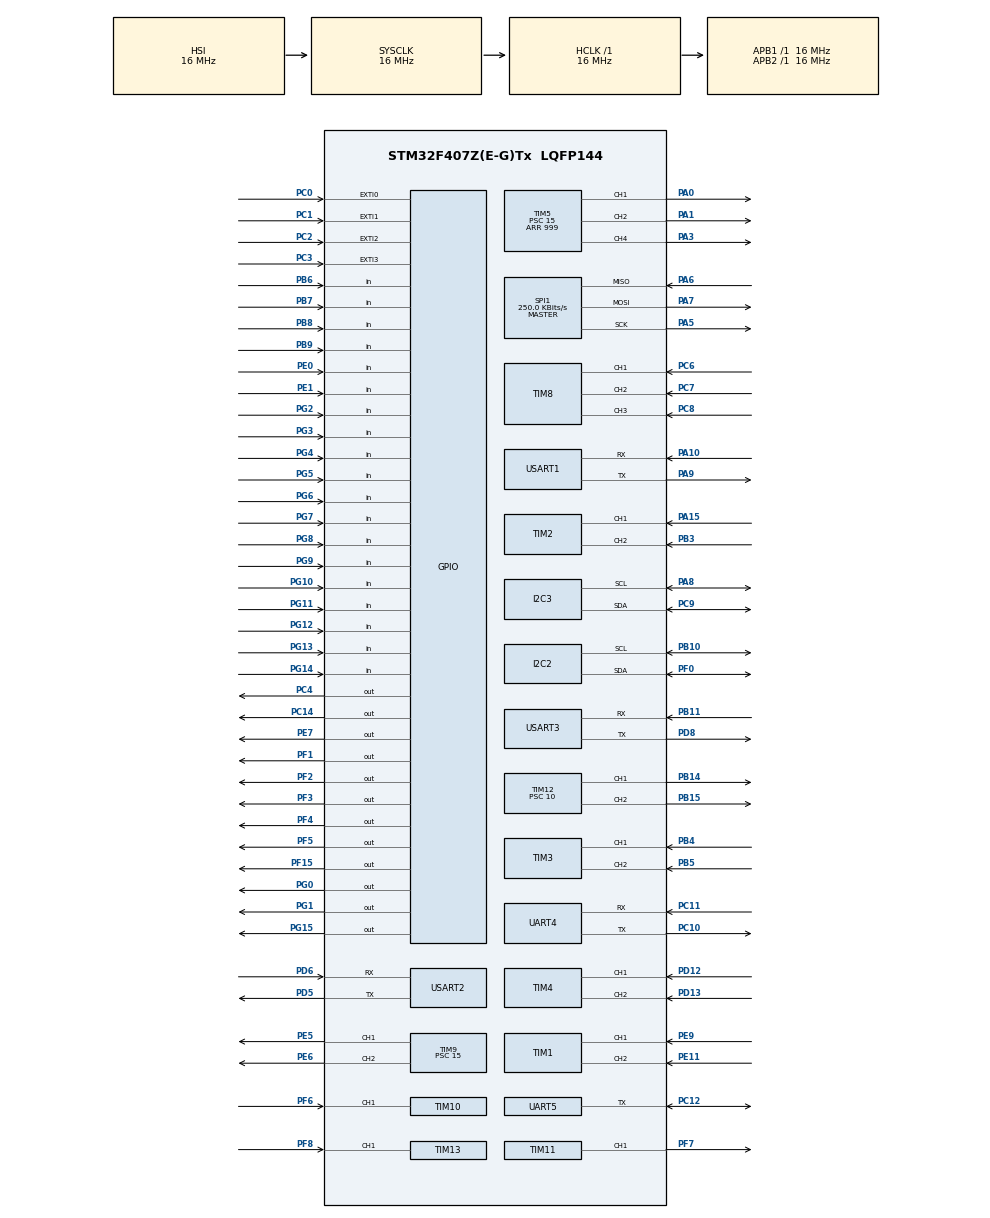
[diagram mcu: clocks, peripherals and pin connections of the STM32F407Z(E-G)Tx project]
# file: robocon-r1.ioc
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Dma.Request0=USART2_RX
Dma.USART2_RX.0.Direction=DMA_PERIPH_TO_MEMORY
Dma.USART2_RX.0.FIFOMode=DMA_FIFOMODE_DISABLE
Dma.USART2_RX.0.Instance=DMA1_Stream5
Dma.USART2_RX.0.MemDataAlignment=DMA_MDATAALIGN_BYTE
Dma.USART2_RX.0.MemInc=DMA_MINC_ENABLE
Dma.USART2_RX.0.Mode=DMA_NORMAL
Dma.USART2_RX.0.PeriphDataAlignment=DMA_PDATAALIGN_BYTE
Dma.USART2_RX.0.PeriphInc=DMA_PINC_DISABLE
Dma.USART2_RX.0.Priority=DMA_PRIORITY_LOW
FREERTOS.Tasks01=defaultTask,24,128,StartDefaultTask,Default,NULL,Dynamic,NULL,NULL
Mcu.Family=STM32F4
Mcu.Name=STM32F407Z(E-G)Tx
Mcu.Package=LQFP144
NVIC.DMA1_Stream5_IRQn=true\:5\:0\:false\:false\:true\:true\:false\:true\:true
NVIC.I2C3_EV_IRQn=true\:5\:0\:false\:false\:true\:true\:true\:true\:true
NVIC.PriorityGroup=NVIC_PRIORITYGROUP_4
NVIC.TIM7_IRQn=true\:15\:0\:false\:false\:true\:false\:false\:true\:true
NVIC.TimeBase=TIM7_IRQn
NVIC.TimeBaseIP=TIM7
NVIC.UART4_IRQn=true\:5\:0\:false\:false\:true\:true\:true\:true\:true
NVIC.UART5_IRQn=true\:5\:0\:false\:false\:true\:true\:true\:true\:true
NVIC.USART1_IRQn=true\:5\:0\:false\:false\:true\:true\:true\:true\:true
NVIC.USART2_IRQn=true\:5\:0\:false\:false\:true\:true\:true\:true\:true
NVIC.USART3_IRQn=true\:5\:0\:false\:false\:true\:true\:true\:true\:true
PA0-WKUP.Signal=S_TIM5_CH1
PA1.Signal=S_TIM5_CH2
PA10.Mode=Asynchronous
PA10.Signal=USART1_RX
PA13.Mode=Serial_Wire
PA13.Signal=SYS_JTMS-SWDIO
PA14.Mode=Serial_Wire
PA14.Signal=SYS_JTCK-SWCLK
PA15.Signal=S_TIM2_CH1_ETR
PA3.Signal=S_TIM5_CH4
PA5.Mode=Full_Duplex_Master
PA5.Signal=SPI1_SCK
PA6.Mode=Full_Duplex_Master
PA6.Signal=SPI1_MISO
PA7.Mode=Full_Duplex_Master
PA7.Signal=SPI1_MOSI
PA8.Mode=I2C
PA8.Signal=I2C3_SCL
PA9.Mode=Asynchronous
PA9.Signal=USART1_TX
PB10.Mode=I2C
PB10.Signal=I2C2_SCL
PB11.Mode=Asynchronous
PB11.Signal=USART3_RX
PB14.Signal=S_TIM12_CH1
PB15.Signal=S_TIM12_CH2
PB3.Signal=S_TIM2_CH2
PB4.Signal=S_TIM3_CH1
PB5.Signal=S_TIM3_CH2
PB6.Signal=GPIO_Input
PB7.Signal=GPIO_Input
PB8.Signal=GPIO_Input
PB9.Signal=GPIO_Input
PC0.Signal=GPXTI0
PC1.Signal=GPXTI1
PC10.Mode=Asynchronous
PC10.Signal=UART4_TX
PC11.Mode=Asynchronous
PC11.Signal=UART4_RX
PC12.Mode=Half_duplex(single_wire_mode)
PC12.Signal=UART5_TX
PC14-OSC32_IN.Signal=GPIO_Output
PC2.Signal=GPXTI2
PC3.Signal=GPXTI3
PC4.Signal=GPIO_Output
PC6.Signal=S_TIM8_CH1
PC7.Signal=S_TIM8_CH2
PC8.Signal=S_TIM8_CH3
PC9.Mode=I2C
PC9.Signal=I2C3_SDA
PD12.Signal=S_TIM4_CH1
PD13.Signal=S_TIM4_CH2
PD5.Mode=Asynchronous
PD5.Signal=USART2_TX
PD6.GPIO_PuPd=GPIO_NOPULL
PD6.Mode=Asynchronous
PD6.Signal=USART2_RX
PD8.Mode=Asynchronous
PD8.Signal=USART3_TX
PE0.Signal=GPIO_Input
PE1.Signal=GPIO_Input
PE11.Signal=S_TIM1_CH2
PE5.Signal=S_TIM9_CH1
PE6.Signal=S_TIM9_CH2
PE7.Signal=GPIO_Output
PE9.Signal=S_TIM1_CH1
PF0.Mode=I2C
PF0.Signal=I2C2_SDA
PF1.Signal=GPIO_Output
PF15.Signal=GPIO_Output
PF2.Signal=GPIO_Output
PF3.Signal=GPIO_Output
PF4.Signal=GPIO_Output
PF5.Signal=GPIO_Output
PF6.Signal=S_TIM10_CH1
PF7.Signal=S_TIM11_CH1
PF8.Signal=S_TIM13_CH1
PG0.Signal=GPIO_Output
PG1.Signal=GPIO_Output
PG10.Signal=GPIO_Input
PG11.Signal=GPIO_Input
PG12.Signal=GPIO_Input
PG13.Signal=GPIO_Input
PG14.Signal=GPIO_Input
PG15.Signal=GPIO_Output
PG2.Signal=GPIO_Input
PG3.Signal=GPIO_Input
PG4.Signal=GPIO_Input
PG5.Signal=GPIO_Input
PG6.Signal=GPIO_Input
PG7.Signal=GPIO_Input
PG8.Signal=GPIO_Input
PG9.Signal=GPIO_Input
ProjectManager.HeapSize=0x200
ProjectManager.StackSize=0x400
ProjectManager.TargetToolchain=CMake
RCC.AHBFreq_Value=16000000
RCC.APB1Freq_Value=16000000
RCC.APB2Freq_Value=16000000
RCC.CortexFreq_Value=16000000
RCC.HSE_VALUE=25000000
RCC.HSI_VALUE=16000000
RCC.LSE_VALUE=32768
RCC.SYSCLKFreq_VALUE=16000000
RCC.VCOOutputFreq_Value=192000000
SH.S_TIM10_CH1.0=TIM10_CH1,Input_Capture1_from_TI1
SH.S_TIM11_CH1.0=TIM11_CH1,PWM Generation1 CH1
SH.S_TIM12_CH1.0=TIM12_CH1,PWM Generation1 CH1
SH.S_TIM12_CH2.0=TIM12_CH2,PWM Generation2 CH2
SH.S_TIM13_CH1.0=TIM13_CH1,Input_Capture1_from_TI1
SH.S_TIM1_CH1.0=TIM1_CH1,Encoder_Interface
SH.S_TIM1_CH2.0=TIM1_CH2,Encoder_Interface
SH.S_TIM2_CH1_ETR.0=TIM2_CH1,Encoder_Interface
SH.S_TIM2_CH2.0=TIM2_CH2,Encoder_Interface
SH.S_TIM3_CH1.0=TIM3_CH1,Encoder_Interface
SH.S_TIM3_CH2.0=TIM3_CH2,Encoder_Interface
SH.S_TIM4_CH1.0=TIM4_CH1,Encoder_Interface
SH.S_TIM4_CH2.0=TIM4_CH2,Encoder_Interface
SH.S_TIM5_CH1.0=TIM5_CH1,PWM Generation1 CH1
SH.S_TIM5_CH2.0=TIM5_CH2,PWM Generation2 CH2
SH.S_TIM5_CH4.0=TIM5_CH4,PWM Generation4 CH4
SH.S_TIM8_CH1.0=TIM8_CH1,Input_Capture1_from_TI1
SH.S_TIM8_CH2.0=TIM8_CH2,Input_Capture2_from_TI2
SH.S_TIM8_CH3.0=TIM8_CH3,Input_Capture3_from_TI3
SH.S_TIM9_CH1.0=TIM9_CH1,PWM Generation1 CH1
SH.S_TIM9_CH2.0=TIM9_CH2,PWM Generation2 CH2
SPI1.BaudRatePrescaler=SPI_BAUDRATEPRESCALER_64
SPI1.CLKPhase=SPI_PHASE_2EDGE
SPI1.CLKPolarity=SPI_POLARITY_HIGH
SPI1.CalculateBaudRate=250.0 KBits/s
SPI1.Direction=SPI_DIRECTION_2LINES
SPI1.FirstBit=SPI_FIRSTBIT_LSB
SPI1.Mode=SPI_MODE_MASTER
SPI1.VirtualType=VM_MASTER
TIM10.Channel=TIM_CHANNEL_1
TIM11.Channel=TIM_CHANNEL_1
TIM12.Channel-PWM\ Generation1\ CH1=TIM_CHANNEL_1
TIM12.Channel-PWM\ Generation2\ CH2=TIM_CHANNEL_2
TIM12.Period=999
TIM12.Prescaler=10
TIM13.Channel=TIM_CHANNEL_1
TIM5.Channel-PWM\ Generation1\ CH1=TIM_CHANNEL_1
TIM5.Channel-PWM\ Generation2\ CH2=TIM_CHANNEL_2
TIM5.Channel-PWM\ Generation4\ CH4=TIM_CHANNEL_4
TIM5.Period=999
TIM5.Prescaler=15
TIM5.Pulse-PWM\ Generation1\ CH1=0
TIM5.Pulse-PWM\ Generation2\ CH2=0
TIM8.Channel-Input_Capture1_from_TI1=TIM_CHANNEL_1
TIM8.Channel-Input_Capture2_from_TI2=TIM_CHANNEL_2
TIM8.Channel-Input_Capture3_from_TI3=TIM_CHANNEL_3
TIM9.Channel-PWM\ Generation1\ CH1=TIM_CHANNEL_1
TIM9.Channel-PWM\ Generation2\ CH2=TIM_CHANNEL_2
TIM9.Period=999
TIM9.Prescaler=15
UART4.VirtualMode=Asynchronous
UART5.VirtualMode=Asynchronous
USART1.VirtualMode=VM_ASYNC
USART2.VirtualMode=VM_ASYNC
USART3.VirtualMode=VM_ASYNC
VP_FREERTOS_VS_CMSIS_V2.Mode=CMSIS_V2
VP_SYS_VS_tim7.Mode=TIM7
VP_TIM10_VS_ClockSourceINT.Mode=Enable_Timer
VP_TIM11_VS_ClockSourceINT.Mode=Enable_Timer
VP_TIM13_VS_ClockSourceINT.Mode=Enable_Timer
VP_TIM8_VS_ClockSourceINT.Mode=Internal
board=custom

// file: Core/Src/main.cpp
/* USER CODE BEGIN Header */
/**
  ******************************************************************************
  * @file           : main.c
  * @brief          : Main program body
  ******************************************************************************
  * @attention
  *
  * Copyright (c) 2026 STMicroelectronics.
  * All rights reserved.
  *
  * This software is licensed under terms that can be found in the LICENSE file
  * in the root directory of this software component.
  * If no LICENSE file comes with this software, it is provided AS-IS.
  *
  ******************************************************************************
  */
/* USER CODE END Header */
#include "main.h"
#include "cmsis_os.h"

/* USER CODE BEGIN Includes */
#include "entry_point.hpp"
#include "bsp_atk_ms901m.hpp"
#include "stm32f4xx_hal_uart.h"
#include "user_controller.hpp"
/* USER CODE END Includes */

I2C_HandleTypeDef hi2c2;
I2C_HandleTypeDef hi2c3;

SPI_HandleTypeDef hspi1;

TIM_HandleTypeDef htim1;
TIM_HandleTypeDef htim2;
TIM_HandleTypeDef htim3;
TIM_HandleTypeDef htim4;
TIM_HandleTypeDef htim5;
TIM_HandleTypeDef htim8;
TIM_HandleTypeDef htim9;
TIM_HandleTypeDef htim10;
TIM_HandleTypeDef htim11;
TIM_HandleTypeDef htim12;
TIM_HandleTypeDef htim13;

UART_HandleTypeDef huart4;
UART_HandleTypeDef huart5;
UART_HandleTypeDef huart1;
UART_HandleTypeDef huart2;
UART_HandleTypeDef huart3;
DMA_HandleTypeDef hdma_usart2_rx;

/* Definitions for defaultTask */
osThreadId_t defaultTaskHandle;
const osThreadAttr_t defaultTask_attributes = {
  .name = "defaultTask",
  .stack_size = 4096,
  .priority = (osPriority_t) osPriorityNormal,
};

void SystemClock_Config(void);
static void MX_GPIO_Init(void);
static void MX_DMA_Init(void);
static void MX_SPI1_Init(void);
static void MX_TIM1_Init(void);
static void MX_TIM2_Init(void);
static void MX_TIM3_Init(void);
static void MX_TIM4_Init(void);
static void MX_UART4_Init(void);
static void MX_TIM8_Init(void);
static void MX_TIM9_Init(void);
static void MX_TIM10_Init(void);
static void MX_TIM11_Init(void);
static void MX_TIM12_Init(void);
static void MX_TIM13_Init(void);
static void MX_I2C2_Init(void);
static void MX_I2C3_Init(void);
static void MX_UART5_Init(void);
static void MX_USART1_UART_Init(void);
static void MX_USART2_UART_Init(void);
static void MX_USART3_UART_Init(void);
static void MX_TIM5_Init(void);
void StartDefaultTask(void *argument);

/* USER CODE BEGIN 0 */
gdut::i2c i2c3{&hi2c3};
gdut::pca9685 pca9685_ctrl{i2c3, gdut::pca9685::default_address};
/* USER CODE END 0 */

int main(void)
{

  /* MCU Configuration--------------------------------------------------------*/

  /* Reset of all peripherals, Initializes the Flash interface and the Systick. */
  HAL_Init();

  /* Configure the system clock */
  SystemClock_Config();

  /* Initialize all configured peripherals */
  MX_GPIO_Init();
  MX_DMA_Init();
  MX_SPI1_Init();
  MX_TIM1_Init();
  MX_TIM2_Init();
  MX_TIM3_Init();
  MX_TIM4_Init();
  MX_UART4_Init();
  MX_TIM8_Init();
  MX_TIM9_Init();
  MX_TIM10_Init();
  MX_TIM11_Init();
  MX_TIM12_Init();
  MX_TIM13_Init();
  MX_I2C2_Init();
  MX_I2C3_Init();
  MX_UART5_Init();
  MX_USART1_UART_Init();
  MX_USART2_UART_Init();
  MX_USART3_UART_Init();
  MX_TIM5_Init();

  /* Init scheduler */
  osKernelInitialize();

  /* USER CODE BEGIN RTOS_QUEUES */
  /* add queues, ... */
  gdut::entry_point::instance().init(
   &pca9685_ctrl, &hi2c2,&hi2c3, &hspi1, &htim1,
   &htim2, &htim3, &htim4, &htim5,
   &htim8, &htim9, &htim10, &htim11, &htim12, &htim13,
   &huart4, &huart5, &huart1, &huart2, &huart3);
  /* USER CODE END RTOS_QUEUES */

  /* Create the thread(s) */
  /* creation of defaultTask */
  defaultTaskHandle = osThreadNew(StartDefaultTask, NULL, &defaultTask_attributes);

  /* Start scheduler */
  osKernelStart();

  /* We should never get here as control is now taken by the scheduler */

  /* Infinite loop */
  while (1)
  {

  }
}

void SystemClock_Config(void)
{
  RCC_OscInitTypeDef RCC_OscInitStruct = {0};
  RCC_ClkInitTypeDef RCC_ClkInitStruct = {0};

  /** Configure the main internal regulator output voltage
  */
  __HAL_RCC_PWR_CLK_ENABLE();
  __HAL_PWR_VOLTAGESCALING_CONFIG(PWR_REGULATOR_VOLTAGE_SCALE1);

  /** Initializes the RCC Oscillators according to the specified parameters
  * in the RCC_OscInitTypeDef structure.
  */
  RCC_OscInitStruct.OscillatorType = RCC_OSCILLATORTYPE_HSI;
  RCC_OscInitStruct.HSIState = RCC_HSI_ON;
  RCC_OscInitStruct.HSICalibrationValue = RCC_HSICALIBRATION_DEFAULT;
  RCC_OscInitStruct.PLL.PLLState = RCC_PLL_NONE;
  if (HAL_RCC_OscConfig(&RCC_OscInitStruct) != HAL_OK)
  {
    Error_Handler();
  }

  /** Initializes the CPU, AHB and APB buses clocks
  */
  RCC_ClkInitStruct.ClockType = RCC_CLOCKTYPE_HCLK|RCC_CLOCKTYPE_SYSCLK
                              |RCC_CLOCKTYPE_PCLK1|RCC_CLOCKTYPE_PCLK2;
  RCC_ClkInitStruct.SYSCLKSource = RCC_SYSCLKSOURCE_HSI;
  RCC_ClkInitStruct.AHBCLKDivider = RCC_SYSCLK_DIV1;
  RCC_ClkInitStruct.APB1CLKDivider = RCC_HCLK_DIV1;
  RCC_ClkInitStruct.APB2CLKDivider = RCC_HCLK_DIV1;

  if (HAL_RCC_ClockConfig(&RCC_ClkInitStruct, FLASH_LATENCY_0) != HAL_OK)
  {
    Error_Handler();
  }
}

static void MX_I2C2_Init(void)
{

  hi2c2.Instance = I2C2;
  hi2c2.Init.ClockSpeed = 100000;
  hi2c2.Init.DutyCycle = I2C_DUTYCYCLE_2;
  hi2c2.Init.OwnAddress1 = 0;
  hi2c2.Init.AddressingMode = I2C_ADDRESSINGMODE_7BIT;
  hi2c2.Init.DualAddressMode = I2C_DUALADDRESS_DISABLE;
  hi2c2.Init.OwnAddress2 = 0;
  hi2c2.Init.GeneralCallMode = I2C_GENERALCALL_DISABLE;
  hi2c2.Init.NoStretchMode = I2C_NOSTRETCH_DISABLE;
  if (HAL_I2C_Init(&hi2c2) != HAL_OK)
  {
    Error_Handler();
  }

}

static void MX_I2C3_Init(void)
{

  hi2c3.Instance = I2C3;
  hi2c3.Init.ClockSpeed = 100000;
  hi2c3.Init.DutyCycle = I2C_DUTYCYCLE_2;
  hi2c3.Init.OwnAddress1 = 0;
  hi2c3.Init.AddressingMode = I2C_ADDRESSINGMODE_7BIT;
  hi2c3.Init.DualAddressMode = I2C_DUALADDRESS_DISABLE;
  hi2c3.Init.OwnAddress2 = 0;
  hi2c3.Init.GeneralCallMode = I2C_GENERALCALL_DISABLE;
  hi2c3.Init.NoStretchMode = I2C_NOSTRETCH_DISABLE;
  if (HAL_I2C_Init(&hi2c3) != HAL_OK)
  {
    Error_Handler();
  }

}

static void MX_SPI1_Init(void)
{

  /* SPI1 parameter configuration*/
  hspi1.Instance = SPI1;
  hspi1.Init.Mode = SPI_MODE_MASTER;
  hspi1.Init.Direction = SPI_DIRECTION_2LINES;
  hspi1.Init.DataSize = SPI_DATASIZE_8BIT;
  hspi1.Init.CLKPolarity = SPI_POLARITY_HIGH;
  hspi1.Init.CLKPhase = SPI_PHASE_2EDGE;
  hspi1.Init.NSS = SPI_NSS_SOFT;
  hspi1.Init.BaudRatePrescaler = SPI_BAUDRATEPRESCALER_64;
  hspi1.Init.FirstBit = SPI_FIRSTBIT_LSB;
  hspi1.Init.TIMode = SPI_TIMODE_DISABLE;
  hspi1.Init.CRCCalculation = SPI_CRCCALCULATION_DISABLE;
  hspi1.Init.CRCPolynomial = 10;
  if (HAL_SPI_Init(&hspi1) != HAL_OK)
  {
    Error_Handler();
  }

}

static void MX_TIM1_Init(void)
{

  TIM_Encoder_InitTypeDef sConfig = {0};
  TIM_MasterConfigTypeDef sMasterConfig = {0};

  htim1.Instance = TIM1;
  htim1.Init.Prescaler = 0;
  htim1.Init.CounterMode = TIM_COUNTERMODE_UP;
  htim1.Init.Period = 65535;
  htim1.Init.ClockDivision = TIM_CLOCKDIVISION_DIV1;
  htim1.Init.RepetitionCounter = 0;
  htim1.Init.AutoReloadPreload = TIM_AUTORELOAD_PRELOAD_DISABLE;
  sConfig.EncoderMode = TIM_ENCODERMODE_TI1;
  sConfig.IC1Polarity = TIM_ICPOLARITY_RISING;
  sConfig.IC1Selection = TIM_ICSELECTION_DIRECTTI;
  sConfig.IC1Prescaler = TIM_ICPSC_DIV1;
  sConfig.IC1Filter = 0;
  sConfig.IC2Polarity = TIM_ICPOLARITY_RISING;
  sConfig.IC2Selection = TIM_ICSELECTION_DIRECTTI;
  sConfig.IC2Prescaler = TIM_ICPSC_DIV1;
  sConfig.IC2Filter = 0;
  if (HAL_TIM_Encoder_Init(&htim1, &sConfig) != HAL_OK)
  {
    Error_Handler();
  }
  sMasterConfig.MasterOutputTrigger = TIM_TRGO_RESET;
  sMasterConfig.MasterSlaveMode = TIM_MASTERSLAVEMODE_DISABLE;
  if (HAL_TIMEx_MasterConfigSynchronization(&htim1, &sMasterConfig) != HAL_OK)
  {
    Error_Handler();
  }

}

static void MX_TIM2_Init(void)
{

  TIM_Encoder_InitTypeDef sConfig = {0};
  TIM_MasterConfigTypeDef sMasterConfig = {0};

  htim2.Instance = TIM2;
  htim2.Init.Prescaler = 0;
  htim2.Init.CounterMode = TIM_COUNTERMODE_UP;
  htim2.Init.Period = 4294967295;
  htim2.Init.ClockDivision = TIM_CLOCKDIVISION_DIV1;
  htim2.Init.AutoReloadPreload = TIM_AUTORELOAD_PRELOAD_DISABLE;
  sConfig.EncoderMode = TIM_ENCODERMODE_TI1;
  sConfig.IC1Polarity = TIM_ICPOLARITY_RISING;
  sConfig.IC1Selection = TIM_ICSELECTION_DIRECTTI;
  sConfig.IC1Prescaler = TIM_ICPSC_DIV1;
  sConfig.IC1Filter = 0;
  sConfig.IC2Polarity = TIM_ICPOLARITY_RISING;
  sConfig.IC2Selection = TIM_ICSELECTION_DIRECTTI;
  sConfig.IC2Prescaler = TIM_ICPSC_DIV1;
  sConfig.IC2Filter = 0;
  if (HAL_TIM_Encoder_Init(&htim2, &sConfig) != HAL_OK)
  {
    Error_Handler();
  }
  sMasterConfig.MasterOutputTrigger = TIM_TRGO_RESET;
  sMasterConfig.MasterSlaveMode = TIM_MASTERSLAVEMODE_DISABLE;
  if (HAL_TIMEx_MasterConfigSynchronization(&htim2, &sMasterConfig) != HAL_OK)
  {
    Error_Handler();
  }

}

static void MX_TIM3_Init(void)
{

  TIM_Encoder_InitTypeDef sConfig = {0};
  TIM_MasterConfigTypeDef sMasterConfig = {0};

  htim3.Instance = TIM3;
  htim3.Init.Prescaler = 0;
  htim3.Init.CounterMode = TIM_COUNTERMODE_UP;
  htim3.Init.Period = 65535;
  htim3.Init.ClockDivision = TIM_CLOCKDIVISION_DIV1;
  htim3.Init.AutoReloadPreload = TIM_AUTORELOAD_PRELOAD_DISABLE;
  sConfig.EncoderMode = TIM_ENCODERMODE_TI1;
  sConfig.IC1Polarity = TIM_ICPOLARITY_RISING;
  sConfig.IC1Selection = TIM_ICSELECTION_DIRECTTI;
  sConfig.IC1Prescaler = TIM_ICPSC_DIV1;
  sConfig.IC1Filter = 0;
  sConfig.IC2Polarity = TIM_ICPOLARITY_RISING;
  sConfig.IC2Selection = TIM_ICSELECTION_DIRECTTI;
  sConfig.IC2Prescaler = TIM_ICPSC_DIV1;
  sConfig.IC2Filter = 0;
  if (HAL_TIM_Encoder_Init(&htim3, &sConfig) != HAL_OK)
  {
    Error_Handler();
  }
  sMasterConfig.MasterOutputTrigger = TIM_TRGO_RESET;
  sMasterConfig.MasterSlaveMode = TIM_MASTERSLAVEMODE_DISABLE;
  if (HAL_TIMEx_MasterConfigSynchronization(&htim3, &sMasterConfig) != HAL_OK)
  {
    Error_Handler();
  }

}

static void MX_TIM4_Init(void)
{

  TIM_Encoder_InitTypeDef sConfig = {0};
  TIM_MasterConfigTypeDef sMasterConfig = {0};

  htim4.Instance = TIM4;
  htim4.Init.Prescaler = 0;
  htim4.Init.CounterMode = TIM_COUNTERMODE_UP;
  htim4.Init.Period = 65535;
  htim4.Init.ClockDivision = TIM_CLOCKDIVISION_DIV1;
  htim4.Init.AutoReloadPreload = TIM_AUTORELOAD_PRELOAD_DISABLE;
  sConfig.EncoderMode = TIM_ENCODERMODE_TI1;
  sConfig.IC1Polarity = TIM_ICPOLARITY_RISING;
  sConfig.IC1Selection = TIM_ICSELECTION_DIRECTTI;
  sConfig.IC1Prescaler = TIM_ICPSC_DIV1;
  sConfig.IC1Filter = 0;
  sConfig.IC2Polarity = TIM_ICPOLARITY_RISING;
  sConfig.IC2Selection = TIM_ICSELECTION_DIRECTTI;
  sConfig.IC2Prescaler = TIM_ICPSC_DIV1;
  sConfig.IC2Filter = 0;
  if (HAL_TIM_Encoder_Init(&htim4, &sConfig) != HAL_OK)
  {
    Error_Handler();
  }
  sMasterConfig.MasterOutputTrigger = TIM_TRGO_RESET;
  sMasterConfig.MasterSlaveMode = TIM_MASTERSLAVEMODE_DISABLE;
  if (HAL_TIMEx_MasterConfigSynchronization(&htim4, &sMasterConfig) != HAL_OK)
  {
    Error_Handler();
  }

}

static void MX_TIM5_Init(void)
{

  TIM_MasterConfigTypeDef sMasterConfig = {0};
  TIM_OC_InitTypeDef sConfigOC = {0};

  htim5.Instance = TIM5;
  htim5.Init.Prescaler = 15;
  htim5.Init.CounterMode = TIM_COUNTERMODE_UP;
  htim5.Init.Period = 999;
  htim5.Init.ClockDivision = TIM_CLOCKDIVISION_DIV1;
  htim5.Init.AutoReloadPreload = TIM_AUTORELOAD_PRELOAD_DISABLE;
  if (HAL_TIM_PWM_Init(&htim5) != HAL_OK)
  {
    Error_Handler();
  }
  sMasterConfig.MasterOutputTrigger = TIM_TRGO_RESET;
  sMasterConfig.MasterSlaveMode = TIM_MASTERSLAVEMODE_DISABLE;
  if (HAL_TIMEx_MasterConfigSynchronization(&htim5, &sMasterConfig) != HAL_OK)
  {
    Error_Handler();
  }
  sConfigOC.OCMode = TIM_OCMODE_PWM1;
  sConfigOC.Pulse = 0;
  sConfigOC.OCPolarity = TIM_OCPOLARITY_HIGH;
  sConfigOC.OCFastMode = TIM_OCFAST_DISABLE;
  if (HAL_TIM_PWM_ConfigChannel(&htim5, &sConfigOC, TIM_CHANNEL_1) != HAL_OK)
  {
    Error_Handler();
  }
  if (HAL_TIM_PWM_ConfigChannel(&htim5, &sConfigOC, TIM_CHANNEL_2) != HAL_OK)
  {
    Error_Handler();
  }
  if (HAL_TIM_PWM_ConfigChannel(&htim5, &sConfigOC, TIM_CHANNEL_4) != HAL_OK)
  {
    Error_Handler();
  }
  HAL_TIM_MspPostInit(&htim5);

}

static void MX_TIM8_Init(void)
{

  TIM_ClockConfigTypeDef sClockSourceConfig = {0};
  TIM_MasterConfigTypeDef sMasterConfig = {0};
  TIM_IC_InitTypeDef sConfigIC = {0};

  htim8.Instance = TIM8;
  htim8.Init.Prescaler = 0;
  htim8.Init.CounterMode = TIM_COUNTERMODE_UP;
  htim8.Init.Period = 65535;
  htim8.Init.ClockDivision = TIM_CLOCKDIVISION_DIV1;
  htim8.Init.RepetitionCounter = 0;
  htim8.Init.AutoReloadPreload = TIM_AUTORELOAD_PRELOAD_DISABLE;
  if (HAL_TIM_Base_Init(&htim8) != HAL_OK)
  {
    Error_Handler();
  }
  sClockSourceConfig.ClockSource = TIM_CLOCKSOURCE_INTERNAL;
  if (HAL_TIM_ConfigClockSource(&htim8, &sClockSourceConfig) != HAL_OK)
  {
    Error_Handler();
  }
  if (HAL_TIM_IC_Init(&htim8) != HAL_OK)
  {
    Error_Handler();
  }
  sMasterConfig.MasterOutputTrigger = TIM_TRGO_RESET;
  sMasterConfig.MasterSlaveMode = TIM_MASTERSLAVEMODE_DISABLE;
  if (HAL_TIMEx_MasterConfigSynchronization(&htim8, &sMasterConfig) != HAL_OK)
  {
    Error_Handler();
  }
  sConfigIC.ICPolarity = TIM_INPUTCHANNELPOLARITY_RISING;
  sConfigIC.ICSelection = TIM_ICSELECTION_DIRECTTI;
  sConfigIC.ICPrescaler = TIM_ICPSC_DIV1;
  sConfigIC.ICFilter = 0;
  if (HAL_TIM_IC_ConfigChannel(&htim8, &sConfigIC, TIM_CHANNEL_1) != HAL_OK)
  {
    Error_Handler();
  }
  if (HAL_TIM_IC_ConfigChannel(&htim8, &sConfigIC, TIM_CHANNEL_2) != HAL_OK)
  {
    Error_Handler();
  }
  if (HAL_TIM_IC_ConfigChannel(&htim8, &sConfigIC, TIM_CHANNEL_3) != HAL_OK)
  {
    Error_Handler();
  }

}

static void MX_TIM9_Init(void)
{

  TIM_OC_InitTypeDef sConfigOC = {0};

  htim9.Instance = TIM9;
  htim9.Init.Prescaler = 15;
  htim9.Init.CounterMode = TIM_COUNTERMODE_UP;
  htim9.Init.Period = 999;
  htim9.Init.ClockDivision = TIM_CLOCKDIVISION_DIV1;
  htim9.Init.AutoReloadPreload = TIM_AUTORELOAD_PRELOAD_DISABLE;
  if (HAL_TIM_PWM_Init(&htim9) != HAL_OK)
  {
    Error_Handler();
  }
  sConfigOC.OCMode = TIM_OCMODE_PWM1;
  sConfigOC.Pulse = 0;
  sConfigOC.OCPolarity = TIM_OCPOLARITY_HIGH;
  sConfigOC.OCFastMode = TIM_OCFAST_DISABLE;
  if (HAL_TIM_PWM_ConfigChannel(&htim9, &sConfigOC, TIM_CHANNEL_1) != HAL_OK)
  {
    Error_Handler();
  }
  if (HAL_TIM_PWM_ConfigChannel(&htim9, &sConfigOC, TIM_CHANNEL_2) != HAL_OK)
  {
    Error_Handler();
  }
  HAL_TIM_MspPostInit(&htim9);

}

static void MX_TIM10_Init(void)
{

  TIM_IC_InitTypeDef sConfigIC = {0};

  htim10.Instance = TIM10;
  htim10.Init.Prescaler = 0;
  htim10.Init.CounterMode = TIM_COUNTERMODE_UP;
  htim10.Init.Period = 65535;
  htim10.Init.ClockDivision = TIM_CLOCKDIVISION_DIV1;
  htim10.Init.AutoReloadPreload = TIM_AUTORELOAD_PRELOAD_DISABLE;
  if (HAL_TIM_Base_Init(&htim10) != HAL_OK)
  {
    Error_Handler();
  }
  if (HAL_TIM_IC_Init(&htim10) != HAL_OK)
  {
    Error_Handler();
  }
  sConfigIC.ICPolarity = TIM_INPUTCHANNELPOLARITY_RISING;
  sConfigIC.ICSelection = TIM_ICSELECTION_DIRECTTI;
  sConfigIC.ICPrescaler = TIM_ICPSC_DIV1;
  sConfigIC.ICFilter = 0;
  if (HAL_TIM_IC_ConfigChannel(&htim10, &sConfigIC, TIM_CHANNEL_1) != HAL_OK)
  {
    Error_Handler();
  }

}

static void MX_TIM11_Init(void)
{

  TIM_OC_InitTypeDef sConfigOC = {0};

  htim11.Instance = TIM11;
  htim11.Init.Prescaler = 0;
  htim11.Init.CounterMode = TIM_COUNTERMODE_UP;
  htim11.Init.Period = 65535;
  htim11.Init.ClockDivision = TIM_CLOCKDIVISION_DIV1;
  htim11.Init.AutoReloadPreload = TIM_AUTORELOAD_PRELOAD_DISABLE;
  if (HAL_TIM_Base_Init(&htim11) != HAL_OK)
  {
    Error_Handler();
  }
  if (HAL_TIM_PWM_Init(&htim11) != HAL_OK)
  {
    Error_Handler();
  }
  sConfigOC.OCMode = TIM_OCMODE_PWM1;
  sConfigOC.Pulse = 0;
  sConfigOC.OCPolarity = TIM_OCPOLARITY_HIGH;
  sConfigOC.OCFastMode = TIM_OCFAST_DISABLE;
  if (HAL_TIM_PWM_ConfigChannel(&htim11, &sConfigOC, TIM_CHANNEL_1) != HAL_OK)
  {
    Error_Handler();
  }
  HAL_TIM_MspPostInit(&htim11);

}

static void MX_TIM12_Init(void)
{

  TIM_OC_InitTypeDef sConfigOC = {0};

  htim12.Instance = TIM12;
  htim12.Init.Prescaler = 5;
  htim12.Init.CounterMode = TIM_COUNTERMODE_UP;
  htim12.Init.Period = 999;
  htim12.Init.ClockDivision = TIM_CLOCKDIVISION_DIV1;
  htim12.Init.AutoReloadPreload = TIM_AUTORELOAD_PRELOAD_DISABLE;
  if (HAL_TIM_PWM_Init(&htim12) != HAL_OK)
  {
    Error_Handler();
  }
  sConfigOC.OCMode = TIM_OCMODE_PWM1;
  sConfigOC.Pulse = 0;
  sConfigOC.OCPolarity = TIM_OCPOLARITY_HIGH;
  sConfigOC.OCFastMode = TIM_OCFAST_DISABLE;
  if (HAL_TIM_PWM_ConfigChannel(&htim12, &sConfigOC, TIM_CHANNEL_1) != HAL_OK)
  {
    Error_Handler();
  }
  if (HAL_TIM_PWM_ConfigChannel(&htim12, &sConfigOC, TIM_CHANNEL_2) != HAL_OK)
  {
    Error_Handler();
  }
  HAL_TIM_MspPostInit(&htim12);

}

static void MX_TIM13_Init(void)
{

  TIM_IC_InitTypeDef sConfigIC = {0};

  htim13.Instance = TIM13;
  htim13.Init.Prescaler = 0;
  htim13.Init.CounterMode = TIM_COUNTERMODE_UP;
  htim13.Init.Period = 65535;
  htim13.Init.ClockDivision = TIM_CLOCKDIVISION_DIV1;
  htim13.Init.AutoReloadPreload = TIM_AUTORELOAD_PRELOAD_DISABLE;
  if (HAL_TIM_Base_Init(&htim13) != HAL_OK)
  {
    Error_Handler();
  }
  if (HAL_TIM_IC_Init(&htim13) != HAL_OK)
  {
    Error_Handler();
  }
  sConfigIC.ICPolarity = TIM_INPUTCHANNELPOLARITY_RISING;
  sConfigIC.ICSelection = TIM_ICSELECTION_DIRECTTI;
  sConfigIC.ICPrescaler = TIM_ICPSC_DIV1;
  sConfigIC.ICFilter = 0;
  if (HAL_TIM_IC_ConfigChannel(&htim13, &sConfigIC, TIM_CHANNEL_1) != HAL_OK)
  {
    Error_Handler();
  }

}

static void MX_UART4_Init(void)
{

  huart4.Instance = UART4;
  huart4.Init.BaudRate = 115200;
  huart4.Init.WordLength = UART_WORDLENGTH_8B;
  huart4.Init.StopBits = UART_STOPBITS_1;
  huart4.Init.Parity = UART_PARITY_NONE;
  huart4.Init.Mode = UART_MODE_TX_RX;
  huart4.Init.HwFlowCtl = UART_HWCONTROL_NONE;
  huart4.Init.OverSampling = UART_OVERSAMPLING_16;
  if (HAL_UART_Init(&huart4) != HAL_OK)
  {
    Error_Handler();
  }

}

static void MX_UART5_Init(void)
{

  huart5.Instance = UART5;
  huart5.Init.BaudRate = 115200;
  huart5.Init.WordLength = UART_WORDLENGTH_8B;
  huart5.Init.StopBits = UART_STOPBITS_1;
  huart5.Init.Parity = UART_PARITY_NONE;
  huart5.Init.Mode = UART_MODE_TX_RX;
  huart5.Init.HwFlowCtl = UART_HWCONTROL_NONE;
  huart5.Init.OverSampling = UART_OVERSAMPLING_16;
  if (HAL_HalfDuplex_Init(&huart5) != HAL_OK)
  {
    Error_Handler();
  }

}

static void MX_USART1_UART_Init(void)
{

  huart1.Instance = USART1;
  huart1.Init.BaudRate = 115200;
  huart1.Init.WordLength = UART_WORDLENGTH_8B;
  huart1.Init.StopBits = UART_STOPBITS_1;
  huart1.Init.Parity = UART_PARITY_NONE;
  huart1.Init.Mode = UART_MODE_TX_RX;
  huart1.Init.HwFlowCtl = UART_HWCONTROL_NONE;
  huart1.Init.OverSampling = UART_OVERSAMPLING_16;
  if (HAL_UART_Init(&huart1) != HAL_OK)
  {
    Error_Handler();
  }

}

static void MX_USART2_UART_Init(void)
{

  huart2.Instance = USART2;
  huart2.Init.BaudRate = 115200;
  huart2.Init.WordLength = UART_WORDLENGTH_8B;
  huart2.Init.StopBits = UART_STOPBITS_1;
  huart2.Init.Parity = UART_PARITY_NONE;
  huart2.Init.Mode = UART_MODE_TX_RX;
  huart2.Init.HwFlowCtl = UART_HWCONTROL_NONE;
  huart2.Init.OverSampling = UART_OVERSAMPLING_16;
  if (HAL_UART_Init(&huart2) != HAL_OK)
  {
    Error_Handler();
  }

}

static void MX_USART3_UART_Init(void)
{

  huart3.Instance = USART3;
  huart3.Init.BaudRate = 115200;
  huart3.Init.WordLength = UART_WORDLENGTH_8B;
  huart3.Init.StopBits = UART_STOPBITS_1;
  huart3.Init.Parity = UART_PARITY_NONE;
  huart3.Init.Mode = UART_MODE_TX_RX;
  huart3.Init.HwFlowCtl = UART_HWCONTROL_NONE;
  huart3.Init.OverSampling = UART_OVERSAMPLING_16;
  if (HAL_UART_Init(&huart3) != HAL_OK)
  {
    Error_Handler();
  }

}

static void MX_DMA_Init(void)
{

  /* DMA controller clock enable */
  __HAL_RCC_DMA1_CLK_ENABLE();

  /* DMA interrupt init */
  /* DMA1_Stream5_IRQn interrupt configuration */
  HAL_NVIC_SetPriority(DMA1_Stream5_IRQn, 5, 0);
  HAL_NVIC_EnableIRQ(DMA1_Stream5_IRQn);

}

static void MX_GPIO_Init(void)
{
  GPIO_InitTypeDef GPIO_InitStruct = {0};

  /* GPIO Ports Clock Enable */
  __HAL_RCC_GPIOE_CLK_ENABLE();
  __HAL_RCC_GPIOC_CLK_ENABLE();
  __HAL_RCC_GPIOF_CLK_ENABLE();
  __HAL_RCC_GPIOA_CLK_ENABLE();
  __HAL_RCC_GPIOG_CLK_ENABLE();
  __HAL_RCC_GPIOB_CLK_ENABLE();
  __HAL_RCC_GPIOD_CLK_ENABLE();

  /*Configure GPIO pin Output Level */
  HAL_GPIO_WritePin(GPIOC, GPIO_PIN_14|GPIO_PIN_4, GPIO_PIN_RESET);

  /*Configure GPIO pin Output Level */
  HAL_GPIO_WritePin(GPIOF, GPIO_PIN_1|GPIO_PIN_2|GPIO_PIN_3|GPIO_PIN_4
                          |GPIO_PIN_5|GPIO_PIN_15, GPIO_PIN_RESET);

  /*Configure GPIO pin Output Level */
  HAL_GPIO_WritePin(GPIOG, GPIO_PIN_0|GPIO_PIN_1|GPIO_PIN_15, GPIO_PIN_RESET);

  /*Configure GPIO pin Output Level */
  HAL_GPIO_WritePin(GPIOE, GPIO_PIN_7, GPIO_PIN_RESET);

  /*Configure GPIO pins : PC14 PC4 */
  GPIO_InitStruct.Pin = GPIO_PIN_14|GPIO_PIN_4;
  GPIO_InitStruct.Mode = GPIO_MODE_OUTPUT_PP;
  GPIO_InitStruct.Pull = GPIO_NOPULL;
  GPIO_InitStruct.Speed = GPIO_SPEED_FREQ_LOW;
  HAL_GPIO_Init(GPIOC, &GPIO_InitStruct);

  /*Configure GPIO pins : PF1 PF2 PF3 PF4
                           PF5 PF15 */
  GPIO_InitStruct.Pin = GPIO_PIN_1|GPIO_PIN_2|GPIO_PIN_3|GPIO_PIN_4
                          |GPIO_PIN_5|GPIO_PIN_15;
  GPIO_InitStruct.Mode = GPIO_MODE_OUTPUT_PP;
  GPIO_InitStruct.Pull = GPIO_NOPULL;
  GPIO_InitStruct.Speed = GPIO_SPEED_FREQ_LOW;
  HAL_GPIO_Init(GPIOF, &GPIO_InitStruct);

  /*Configure GPIO pins : PC0 PC1 PC2 PC3 */
  GPIO_InitStruct.Pin = GPIO_PIN_0|GPIO_PIN_1|GPIO_PIN_2|GPIO_PIN_3;
  GPIO_InitStruct.Mode = GPIO_MODE_IT_RISING;
  GPIO_InitStruct.Pull = GPIO_NOPULL;
  HAL_GPIO_Init(GPIOC, &GPIO_InitStruct);

  /*Configure GPIO pins : PG0 PG1 PG15 */
  GPIO_InitStruct.Pin = GPIO_PIN_0|GPIO_PIN_1|GPIO_PIN_15;
  GPIO_InitStruct.Mode = GPIO_MODE_OUTPUT_PP;
  GPIO_InitStruct.Pull = GPIO_NOPULL;
  GPIO_InitStruct.Speed = GPIO_SPEED_FREQ_LOW;
  HAL_GPIO_Init(GPIOG, &GPIO_InitStruct);

  /*Configure GPIO pin : PE7 */
  GPIO_InitStruct.Pin = GPIO_PIN_7;
  GPIO_InitStruct.Mode = GPIO_MODE_OUTPUT_PP;
  GPIO_InitStruct.Pull = GPIO_NOPULL;
  GPIO_InitStruct.Speed = GPIO_SPEED_FREQ_LOW;
  HAL_GPIO_Init(GPIOE, &GPIO_InitStruct);

  /*Configure GPIO pins : PG2 PG3 PG4 PG5
                           PG6 PG7 PG8 PG9
                           PG10 PG11 PG12 PG13
                           PG14 */
  GPIO_InitStruct.Pin = GPIO_PIN_2|GPIO_PIN_3|GPIO_PIN_4|GPIO_PIN_5
                          |GPIO_PIN_6|GPIO_PIN_7|GPIO_PIN_8|GPIO_PIN_9
                          |GPIO_PIN_10|GPIO_PIN_11|GPIO_PIN_12|GPIO_PIN_13
                          |GPIO_PIN_14;
  GPIO_InitStruct.Mode = GPIO_MODE_INPUT;
  GPIO_InitStruct.Pull = GPIO_NOPULL;
  HAL_GPIO_Init(GPIOG, &GPIO_InitStruct);

  /*Configure GPIO pins : PB6 PB7 PB8 PB9 */
  GPIO_InitStruct.Pin = GPIO_PIN_6|GPIO_PIN_7|GPIO_PIN_8|GPIO_PIN_9;
  GPIO_InitStruct.Mode = GPIO_MODE_INPUT;
  GPIO_InitStruct.Pull = GPIO_NOPULL;
  HAL_GPIO_Init(GPIOB, &GPIO_InitStruct);

  /*Configure GPIO pins : PE0 PE1 */
  GPIO_InitStruct.Pin = GPIO_PIN_0|GPIO_PIN_1;
  GPIO_InitStruct.Mode = GPIO_MODE_INPUT;
  GPIO_InitStruct.Pull = GPIO_NOPULL;
  HAL_GPIO_Init(GPIOE, &GPIO_InitStruct);

}

/* USER CODE BEGIN 4 */
// extern "C" int __io_putchar(int ch)
// {
//   uint8_t byte = static_cast<uint8_t>(ch);
//   HAL_UART_Transmit(&huart4, &byte, 1U, 10U);
//   return ch;
// }

extern "C" void HAL_UARTEx_RxEventCallback(UART_HandleTypeDef *huart, uint16_t Size) {
  if (huart->Instance == USART2) {
    gdut::entry_point::instance().uart2_rx_callback(Size);
  } else if (huart->Instance == UART4) {
    gdut::entry_point::instance().uart4_rx_callback(Size);
  }
}

extern "C" void HAL_UART_ErrorCallback(UART_HandleTypeDef *huart) {
  /*if (huart->Instance == USART2) {
    // ms901.handle_error_rx();
     user_controller.transfer().rx_event_callback(Size);
  }else if (huart->Instance == UART4) {
    // ms901.handle_error_rx();
  }*/
}
/* USER CODE END 4 */

void StartDefaultTask(void *argument)
{
  /* USER CODE BEGIN 5 */
  // 启动主程序
  gdut::entry_point::instance().start();
  /* Infinite loop */
  for(;;)
  {
    osDelay(1000);
  }
  /* USER CODE END 5 */
}

void HAL_TIM_PeriodElapsedCallback(TIM_HandleTypeDef *htim)
{
  if (htim->Instance == TIM7)
  {
    HAL_IncTick();
  }
}

void Error_Handler(void)
{
  __disable_irq();
  while (1)
  {
  }
}
